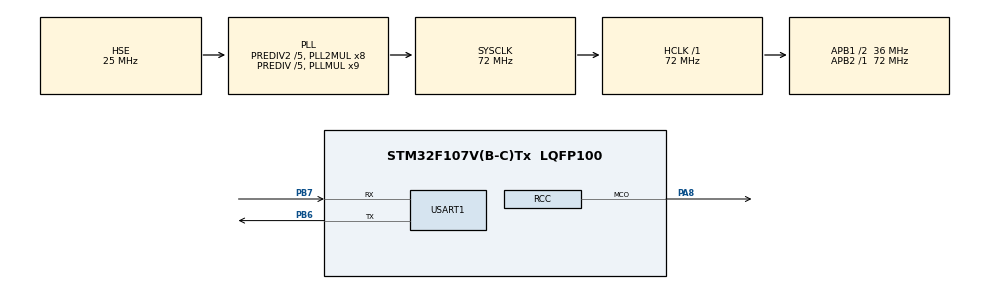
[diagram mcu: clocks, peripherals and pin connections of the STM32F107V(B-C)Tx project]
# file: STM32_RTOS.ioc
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FREERTOS.Tasks01=myTask02,0,128,StartTask02,Default,NULL,Dynamic,NULL,NULL;myTask03,-1,128,StartTask03,Default,NULL,Dynamic,NULL,NULL;myTask01,1,128,StartTask01,Default,NULL,Dynamic,NULL,NULL
FREERTOS.configUSE_NEWLIB_REENTRANT=1
Mcu.Family=STM32F1
Mcu.Name=STM32F107V(B-C)Tx
Mcu.Package=LQFP100
NVIC.PriorityGroup=NVIC_PRIORITYGROUP_4
NVIC.TIM3_IRQn=true\:15\:0\:false\:false\:true\:false\:false\:true\:true
NVIC.TimeBase=TIM3_IRQn
NVIC.TimeBaseIP=TIM3
NVIC.USART1_IRQn=true\:5\:0\:false\:false\:true\:true\:true\:true\:true
OSC_IN.Mode=HSE-External-Oscillator
OSC_IN.Signal=RCC_OSC_IN
OSC_OUT.Mode=HSE-External-Oscillator
OSC_OUT.Signal=RCC_OSC_OUT
PA13.Mode=Serial_Wire
PA13.Signal=SYS_JTMS-SWDIO
PA14.Mode=Serial_Wire
PA14.Signal=SYS_JTCK-SWCLK
PA8.GPIO_Speed=GPIO_SPEED_FREQ_MEDIUM
PA8.Mode=Clock-out
PA8.Signal=RCC_MCO
PB6.Mode=Asynchronous
PB6.Signal=USART1_TX
PB7.Mode=Asynchronous
PB7.Signal=USART1_RX
ProjectManager.HeapSize=0x200
ProjectManager.StackSize=0x400
ProjectManager.TargetToolchain=STM32CubeIDE
RCC.AHBFreq_Value=72000000
RCC.APB1CLKDivider=RCC_HCLK_DIV2
RCC.APB1Freq_Value=36000000
RCC.APB1TimFreq_Value=72000000
RCC.APB2Freq_Value=72000000
RCC.APB2TimFreq_Value=72000000
RCC.HCLKFreq_Value=72000000
RCC.HSEDivPLL=RCC_HSE_PREDIV_DIV5
RCC.HSE_VALUE=25000000
RCC.PLL3Mul=RCC_PLLI2S_MUL10
RCC.PLLMUL=RCC_PLL_MUL9
RCC.PLLSourceVirtual=RCC_PLLSOURCE_HSE
RCC.Prediv1Source=RCC_PREDIV1_SOURCE_PLL2
RCC.Prediv2=RCC_HSE_PREDIV2_DIV5
RCC.RCC_MCOSource=RCC_MCO1SOURCE_PLL3CLK
RCC.SYSCLKFreq_VALUE=72000000
RCC.SYSCLKSource=RCC_SYSCLKSOURCE_PLLCLK
RCC.USBFreq_Value=48000000
USART1.VirtualMode=VM_ASYNC
VP_FREERTOS_VS_CMSIS_V1.Mode=CMSIS_V1
VP_SYS_VS_tim3.Mode=TIM3
board=custom

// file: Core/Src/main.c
/* USER CODE BEGIN Header */
/**
  ******************************************************************************
  * @file           : main.c
  * @brief          : Main program body
  ******************************************************************************
  * @attention
  *
  * Copyright (c) 2024 STMicroelectronics.
  * All rights reserved.
  *
  * This software is licensed under terms that can be found in the LICENSE file
  * in the root directory of this software component.
  * If no LICENSE file comes with this software, it is provided AS-IS.
  *
  ******************************************************************************
  */
/* USER CODE END Header */
#include "main.h"
#include "cmsis_os.h"

UART_HandleTypeDef huart1;

osThreadId myTask02Handle;
osThreadId myTask03Handle;
osThreadId myTask01Handle;

void SystemClock_Config(void);
static void MX_GPIO_Init(void);
static void MX_USART1_UART_Init(void);
void StartTask02(void const * argument);
void StartTask03(void const * argument);
void StartTask01(void const * argument);

int main(void)
{

  /* MCU Configuration--------------------------------------------------------*/

  /* Reset of all peripherals, Initializes the Flash interface and the Systick. */
  HAL_Init();

  /* Configure the system clock */
  SystemClock_Config();

  /* Initialize all configured peripherals */
  MX_GPIO_Init();
  MX_USART1_UART_Init();

  /* Create the thread(s) */
  /* definition and creation of myTask02 */
  osThreadDef(myTask02, StartTask02, osPriorityNormal, 0, 128);
  myTask02Handle = osThreadCreate(osThread(myTask02), NULL);

  /* definition and creation of myTask03 */
  osThreadDef(myTask03, StartTask03, osPriorityBelowNormal, 0, 128);
  myTask03Handle = osThreadCreate(osThread(myTask03), NULL);

  /* definition and creation of myTask01 */
  osThreadDef(myTask01, StartTask01, osPriorityAboveNormal, 0, 128);
  myTask01Handle = osThreadCreate(osThread(myTask01), NULL);

  /* Start scheduler */
  osKernelStart();

  /* We should never get here as control is now taken by the scheduler */

  /* Infinite loop */
  while (1)
  {

  }
}

void SystemClock_Config(void)
{
  RCC_OscInitTypeDef RCC_OscInitStruct = {0};
  RCC_ClkInitTypeDef RCC_ClkInitStruct = {0};

  /** Initializes the RCC Oscillators according to the specified parameters
  * in the RCC_OscInitTypeDef structure.
  */
  RCC_OscInitStruct.OscillatorType = RCC_OSCILLATORTYPE_HSE;
  RCC_OscInitStruct.HSEState = RCC_HSE_ON;
  RCC_OscInitStruct.HSEPredivValue = RCC_HSE_PREDIV_DIV5;
  RCC_OscInitStruct.HSIState = RCC_HSI_ON;
  RCC_OscInitStruct.Prediv1Source = RCC_PREDIV1_SOURCE_PLL2;
  RCC_OscInitStruct.PLL.PLLState = RCC_PLL_ON;
  RCC_OscInitStruct.PLL.PLLSource = RCC_PLLSOURCE_HSE;
  RCC_OscInitStruct.PLL.PLLMUL = RCC_PLL_MUL9;
  RCC_OscInitStruct.PLL2.PLL2State = RCC_PLL2_ON;
  RCC_OscInitStruct.PLL2.PLL2MUL = RCC_PLL2_MUL8;
  RCC_OscInitStruct.PLL2.HSEPrediv2Value = RCC_HSE_PREDIV2_DIV5;
  if (HAL_RCC_OscConfig(&RCC_OscInitStruct) != HAL_OK)
  {
    Error_Handler();
  }

  /** Initializes the CPU, AHB and APB buses clocks
  */
  RCC_ClkInitStruct.ClockType = RCC_CLOCKTYPE_HCLK|RCC_CLOCKTYPE_SYSCLK
                              |RCC_CLOCKTYPE_PCLK1|RCC_CLOCKTYPE_PCLK2;
  RCC_ClkInitStruct.SYSCLKSource = RCC_SYSCLKSOURCE_PLLCLK;
  RCC_ClkInitStruct.AHBCLKDivider = RCC_SYSCLK_DIV1;
  RCC_ClkInitStruct.APB1CLKDivider = RCC_HCLK_DIV2;
  RCC_ClkInitStruct.APB2CLKDivider = RCC_HCLK_DIV1;

  if (HAL_RCC_ClockConfig(&RCC_ClkInitStruct, FLASH_LATENCY_2) != HAL_OK)
  {
    Error_Handler();
  }
  HAL_RCC_MCOConfig(RCC_MCO, RCC_MCO1SOURCE_PLL3CLK, RCC_MCODIV_1);

  /** Configure the Systick interrupt time
  */
  __HAL_RCC_HSE_PREDIV2_CONFIG(RCC_HSE_PREDIV2_DIV5);

  /** Configure the Systick interrupt time
  */
  __HAL_RCC_PLLI2S_CONFIG(RCC_PLLI2S_MUL10);

  /** Configure the Systick interrupt time
  */
  __HAL_RCC_PLLI2S_ENABLE();
}

static void MX_USART1_UART_Init(void)
{

  huart1.Instance = USART1;
  huart1.Init.BaudRate = 115200;
  huart1.Init.WordLength = UART_WORDLENGTH_8B;
  huart1.Init.StopBits = UART_STOPBITS_1;
  huart1.Init.Parity = UART_PARITY_NONE;
  huart1.Init.Mode = UART_MODE_TX_RX;
  huart1.Init.HwFlowCtl = UART_HWCONTROL_NONE;
  huart1.Init.OverSampling = UART_OVERSAMPLING_16;
  if (HAL_UART_Init(&huart1) != HAL_OK)
  {
    Error_Handler();
  }

}

static void MX_GPIO_Init(void)
{
  GPIO_InitTypeDef GPIO_InitStruct = {0};

  /* GPIO Ports Clock Enable */
  __HAL_RCC_GPIOA_CLK_ENABLE();
  __HAL_RCC_GPIOB_CLK_ENABLE();

  /*Configure GPIO pin : PA8 */
  GPIO_InitStruct.Pin = GPIO_PIN_8;
  GPIO_InitStruct.Mode = GPIO_MODE_AF_PP;
  GPIO_InitStruct.Speed = GPIO_SPEED_FREQ_MEDIUM;
  HAL_GPIO_Init(GPIOA, &GPIO_InitStruct);

}

void StartTask02(void const * argument)
{
  /* USER CODE BEGIN 5 */
	char buf[] = "Hello From Task2 Who have Normal Priority\n";
  /* Infinite loop */
  for(;;)
  {
	  HAL_UART_Transmit(&huart1,(uint8_t *)buf,sizeof(buf)-1,HAL_MAX_DELAY);
	  osDelay(1000);
  }
  /* USER CODE END 5 */
}

void StartTask03(void const * argument)
{
  /* USER CODE BEGIN StartTask03 */
	char buf[] = "Hello From Task3 Who have Below the Normal Priority\n\n";
  /* Infinite loop */
  for(;;)
  {
	  HAL_UART_Transmit(&huart1,(uint8_t *)buf,sizeof(buf)-1,HAL_MAX_DELAY);
	  osDelay(1000);
  }
  /* USER CODE END StartTask03 */
}

void StartTask01(void const * argument)
{
  /* USER CODE BEGIN StartTask01 */
	char buf[] = "\nHello From Task1 Who have Above the Normal Priority\n";
  /* Infinite loop */
  for(;;)
  {
	HAL_UART_Transmit(&huart1,(uint8_t *)buf,sizeof(buf)-1,HAL_MAX_DELAY);
    osDelay(1000);
  }
  /* USER CODE END StartTask01 */
}

void HAL_TIM_PeriodElapsedCallback(TIM_HandleTypeDef *htim)
{
  if (htim->Instance == TIM3) {
    HAL_IncTick();
  }
}

void Error_Handler(void)
{
  __disable_irq();
  while (1)
  {
  }
}
